AUTOSAR XML (schema 4.0)
standard types defined: float32, float64, sint16, sint32, sint8, uint16, uint32, uint8, void, boolean
package /ImplDataTypes
  7 x impl type, all with category=TYPE_REFERENCE, type-emitter=RTE:
    Impl_SensorPositionType: implementation-data-type=sint32
    Impl_SensorWeightType: implementation-data-type=uint32
    IoPositionSensorReadingType: implementation-data-type=Impl_SensorPositionType
    IoWeightSensorReadingType: implementation-data-type=Impl_SensorPositionType
    MultiStateBtnType: implementation-data-type=uint8
    SeatModeBtnType: implementation-data-type=boolean
    StepMotorStepType: implementation-data-type=uint8
package /MappingSets
  data type mapping set MappingSet: mode-request-type-map{implementation-data-type=uint8, mode-group=SeatCtrlMode}
package /PortInterfaces/ClientServer
  6 x client server interface:
    CsIf_IoGetSensorPosition
      operation Opr_IOGet
        arg position: type=IoPositionSensorReadingType, direction=OUT
    CsIf_IoGetSensorWeight
      operation Opr_IOGet
        arg weight: type=IoWeightSensorReadingType, direction=OUT
    CsIf_IoSetMotor
      operation Opr_IOSetForward
      operation Opr_IOSetReversed
    CsIf_PositionSensor
      operation Opr_GetPosition
        arg position: type=Impl_SensorPositionType, direction=OUT
    CsIf_StepMotor
      operation Opr_Move
        arg Arg_step: type=StepMotorStepType, direction=IN
    CsIf_WeightSensor
      operation GetWeight
        arg weight: type=Impl_SensorWeightType, direction=OUT
package /PortInterfaces/ModeSwitch
  mode switch interface MsIf_SeatCtrlMode
    mode group SeatCtrlMode: type=SeatCtrlMode
  mode declaration group SeatCtrlMode: category=ALPHABETIC_ORDER, initial-mode=INIT, on-transition-value=255
    mode AUTO
    mode INIT
    mode MANUAL
package /PortInterfaces/SenderReceiver
  sender receiver interface SrIf_SeatCtrlBtns
    data DE_HeightBtnState: type=MultiStateBtnType
    data DE_InclineBtnState: type=MultiStateBtnType
    data DE_SlideBtnState: type=MultiStateBtnType
  sender receiver interface SrIf_SeatCtrlData
    data DE_Height: type=uint8
    data DE_Incline: type=uint8
    data DE_Slide: type=uint8
  sender receiver interface SrIf_SeatModeBtn
    data SeatModeBtn: type=SeatModeBtnType
package /SoftwareComponents
  11 x swc implementation, all with programming-language=C, sw-version=1.0.0, vendor-id=255:
    Impl_SWC_ECU1: behavior=Ibhv_SWC_ECU1
      code-descriptors:
        code Code: artifact-descriptors=autosar-engineering-object={short-label=SWC.c, category=SWSRC}
      resource consumption ResourceConsumption
    Impl_SWC_HMI: behavior=Ibhv_SWC_HMI
      code-descriptors:
        code Code: artifact-descriptors=autosar-engineering-object={short-label=SWC.c, category=SWSRC}
      resource consumption ResourceConsumption
    Impl_SWC_HeightMotor: behavior=Ibhv_SWC_HeightMotor
      code-descriptors:
        code Code: artifact-descriptors=autosar-engineering-object={short-label=SWC.c, category=SWSRC}
      resource consumption ResourceConsumption
    Impl_SWC_HeightSensor: behavior=Ibhv_SWC_HeightSensor
      code-descriptors:
        code Code: artifact-descriptors=autosar-engineering-object={short-label=SWC.c, category=SWSRC}
      resource consumption ResourceConsumption
    Impl_SWC_InclineMotor: behavior=Ibhv_SWC_InclineMotor
      code-descriptors:
        code Code: artifact-descriptors=autosar-engineering-object={short-label=SWC.c, category=SWSRC}
      resource consumption ResourceConsumption
    Impl_SWC_InclineSensor: behavior=Ibhv_SWC_InclineSensor
      code-descriptors:
        code Code: artifact-descriptors=autosar-engineering-object={short-label=SWC.c, category=SWSRC}
      resource consumption ResourceConsumption
    Impl_SWC_IoHwAbs: behavior=Ibhv_SWC_IoHwAbs
      code-descriptors:
        code Code: artifact-descriptors=autosar-engineering-object={short-label=SWC.c, category=SWSRC}
      resource consumption ResourceConsumption
    Impl_SWC_SeatMgr: behavior=Ibhv_SWC_SeatMgr
      code-descriptors:
        code Code: artifact-descriptors=autosar-engineering-object={short-label=SWC.c, category=SWSRC}
      resource consumption ResourceConsumption
    Impl_SWC_SlideMotor: behavior=Ibhv_SWC_SlideMotor
      code-descriptors:
        code Code: artifact-descriptors=autosar-engineering-object={short-label=SWC.c, category=SWSRC}
      resource consumption ResourceConsumption
    Impl_SWC_SlideSensor: behavior=Ibhv_SWC_SlideSensor
      code-descriptors:
        code Code: artifact-descriptors=autosar-engineering-object={short-label=SWC.c, category=SWSRC}
      resource consumption ResourceConsumption
    Impl_SWC_WeightSensor: behavior=Ibhv_SWC_WeightSensor
      code-descriptors:
        code Code: artifact-descriptors=autosar-engineering-object={short-label=SWC.c, category=SWSRC}
      resource consumption ResourceConsumption
  application sw component type SWC_ECU1
    provide port pp_SeatCtrlData: provided-interface=SrIf_SeatCtrlData
    behavior Ibhv_SWC_ECU1: data-type-mapping=MappingSet, handle-termination-and-restart=NO-SUPPORT
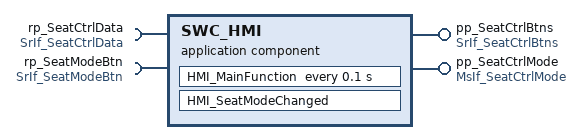
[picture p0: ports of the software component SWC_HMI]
  application sw component type SWC_HMI
    provide port pp_SeatCtrlBtns: provided-interface=SrIf_SeatCtrlBtns
    provide port pp_SeatCtrlMode: provided-interface=MsIf_SeatCtrlMode
    require port rp_SeatCtrlData: required-interface=SrIf_SeatCtrlData
    require port rp_SeatModeBtn: required-interface=SrIf_SeatModeBtn
    behavior Ibhv_SWC_HMI: data-type-mapping=MappingSet, handle-termination-and-restart=NO-SUPPORT
      data received event DRE_rp_SeatModeBtn_SeatModeBtn: start-on-event=HMI_SeatModeChanged, data=rp_SeatModeBtn.SeatModeBtn
      timing event TE_HMI_MainFunction_100ms: start-on-event=HMI_MainFunction, period=0.1
      runnable HMI_MainFunction
        data-receive-point-by-arguments:
          access DRP_rp_SeatCtrlData_DE_Height: accessed-variable=rp_SeatCtrlData.DE_Height
          access DRP_rp_SeatCtrlData_DE_Incline: accessed-variable=rp_SeatCtrlData.DE_Incline
          access DRP_rp_SeatCtrlData_DE_Slide: accessed-variable=rp_SeatCtrlData.DE_Slide
        data-send-points:
          access DSP_pp_SeatCtrlBtns_DE_HeightBtnState: accessed-variable=pp_SeatCtrlBtns.DE_HeightBtnState
          access DSP_pp_SeatCtrlBtns_DE_InclineBtnState: accessed-variable=pp_SeatCtrlBtns.DE_InclineBtnState
          access DSP_pp_SeatCtrlBtns_DE_SlideBtnState: accessed-variable=pp_SeatCtrlBtns.DE_SlideBtnState
      runnable HMI_SeatModeChanged
        data-receive-point-by-arguments:
          access DRP_rp_SeatModeBtn_SeatModeBtn: accessed-variable=rp_SeatModeBtn.SeatModeBtn
        mode switch point MSP_pp_SeatCtrlMode_pp_SeatCtrlMode: mode-group=pp_SeatCtrlMode.SeatCtrlMode
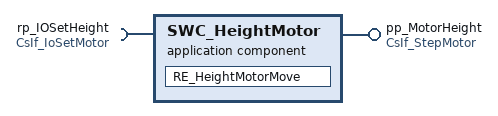
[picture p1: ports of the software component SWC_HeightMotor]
  application sw component type SWC_HeightMotor
    provide port pp_MotorHeight: provided-interface=CsIf_StepMotor
    require port rp_IOSetHeight: required-interface=CsIf_IoSetMotor
    behavior Ibhv_SWC_HeightMotor: data-type-mapping=MappingSet, handle-termination-and-restart=NO-SUPPORT
      operation invoked event OIE_pp_MotorHeight_Opr_Move: start-on-event=RE_HeightMotorMove, operation=pp_MotorHeight.Opr_Move
      runnable RE_HeightMotorMove
        sync call SCP_rp_IOSetHeight_Opr_IOSetForward: operation=rp_IOSetHeight.Opr_IOSetForward, timeout=0.0
        sync call SCP_rp_IOSetHeight_Opr_IOSetReversed: operation=rp_IOSetHeight.Opr_IOSetReversed, timeout=0.0
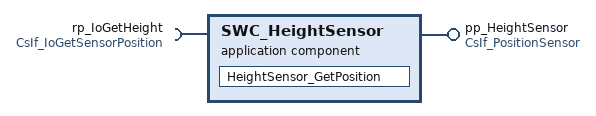
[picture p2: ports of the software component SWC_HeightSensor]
  application sw component type SWC_HeightSensor
    provide port pp_HeightSensor: provided-interface=CsIf_PositionSensor
    require port rp_IoGetHeight: required-interface=CsIf_IoGetSensorPosition
    behavior Ibhv_SWC_HeightSensor: data-type-mapping=MappingSet, handle-termination-and-restart=NO-SUPPORT
      operation invoked event OIE_pp_HeightSensor_Opr_GetPosition: start-on-event=HeightSensor_GetPosition, operation=pp_HeightSensor.Opr_GetPosition
      runnable HeightSensor_GetPosition
        sync call SCP_rp_IoGetHeight_Opr_IOGet: operation=rp_IoGetHeight.Opr_IOGet, timeout=0.0
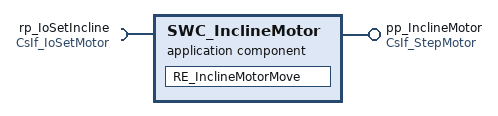
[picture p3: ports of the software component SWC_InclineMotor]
  application sw component type SWC_InclineMotor
    provide port pp_InclineMotor: provided-interface=CsIf_StepMotor
    require port rp_IoSetIncline: required-interface=CsIf_IoSetMotor
    behavior Ibhv_SWC_InclineMotor: data-type-mapping=MappingSet, handle-termination-and-restart=NO-SUPPORT
      operation invoked event OIE_pp_InclineMotor_Opr_Move: start-on-event=RE_InclineMotorMove, operation=pp_InclineMotor.Opr_Move
      runnable RE_InclineMotorMove
        sync call SCP_rp_IoSetIncline_Opr_IOSetForward: operation=rp_IoSetIncline.Opr_IOSetForward, timeout=0.0
        sync call SCP_rp_IoSetIncline_Opr_IOSetReversed: operation=rp_IoSetIncline.Opr_IOSetReversed, timeout=0.0
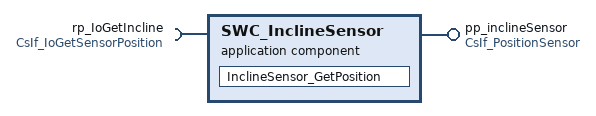
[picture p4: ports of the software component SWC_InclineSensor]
  application sw component type SWC_InclineSensor
    provide port pp_inclineSensor: provided-interface=CsIf_PositionSensor
    require port rp_IoGetIncline: required-interface=CsIf_IoGetSensorPosition
    behavior Ibhv_SWC_InclineSensor: data-type-mapping=MappingSet, handle-termination-and-restart=NO-SUPPORT
      operation invoked event OIE_pp_inclineSensor_Opr_GetPosition: start-on-event=InclineSensor_GetPosition, operation=pp_inclineSensor.Opr_GetPosition
      runnable InclineSensor_GetPosition
        sync call SCP_rp_IoGetIncline_Opr_IOGet: operation=rp_IoGetIncline.Opr_IOGet, timeout=0.0
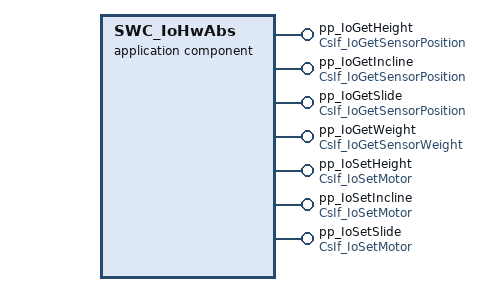
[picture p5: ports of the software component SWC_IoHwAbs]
  application sw component type SWC_IoHwAbs
    7 x provide port:
      pp_IoGetHeight: provided-interface=CsIf_IoGetSensorPosition
      pp_IoGetIncline: provided-interface=CsIf_IoGetSensorPosition
      pp_IoGetSlide: provided-interface=CsIf_IoGetSensorPosition
      pp_IoGetWeight: provided-interface=CsIf_IoGetSensorWeight
      pp_IoSetHeight: provided-interface=CsIf_IoSetMotor
      pp_IoSetIncline: provided-interface=CsIf_IoSetMotor
      pp_IoSetSlide: provided-interface=CsIf_IoSetMotor
    behavior Ibhv_SWC_IoHwAbs: data-type-mapping=MappingSet, handle-termination-and-restart=NO-SUPPORT
      10 x operation invoked event:
        OIE_pp_IoGetHeight_Opr_IOGet: start-on-event=IOHwAbs_ECU_GetHeight, operation=pp_IoGetHeight.Opr_IOGet
        OIE_pp_IoGetIncline_Opr_IOGet: start-on-event=IOHwAbs_ECU_GetIncline, operation=pp_IoGetIncline.Opr_IOGet
        OIE_pp_IoGetSlide_Opr_IOGet: start-on-event=IOHwAbs_ECU_GetSlide, operation=pp_IoGetSlide.Opr_IOGet
        OIE_pp_IoGetWeight_Opr_IOGet: start-on-event=IOHwAbs_ECU_GetWeight, operation=pp_IoGetWeight.Opr_IOGet
        OIE_pp_IoSetHeight_Opr_IOSetForward: start-on-event=IOHwAbs_ECU_SetForwardHeight, operation=pp_IoSetHeight.Opr_IOSetForward
        OIE_pp_IoSetHeight_Opr_IOSetReversed: start-on-event=IOHwAbs_ECU_SetReverseHeight, operation=pp_IoSetHeight.Opr_IOSetReversed
        OIE_pp_IoSetIncline_Opr_IOSetForward: start-on-event=IOHwAbs_ECU_SetForwardIncline, operation=pp_IoSetIncline.Opr_IOSetForward
        OIE_pp_IoSetIncline_Opr_IOSetReversed: start-on-event=IOHwAbs_ECU_SetReverseIncline, operation=pp_IoSetIncline.Opr_IOSetReversed
        OIE_pp_IoSetSlide_Opr_IOSetForward: start-on-event=IOHwAbs_ECU_SetForwardSlide, operation=pp_IoSetSlide.Opr_IOSetForward
        OIE_pp_IoSetSlide_Opr_IOSetReversed: start-on-event=IOHwAbs_ECU_SetReverseSlide, operation=pp_IoSetSlide.Opr_IOSetReversed
      10 x runnable:
        IOHwAbs_ECU_GetHeight
        IOHwAbs_ECU_GetIncline
        IOHwAbs_ECU_GetSlide
        IOHwAbs_ECU_GetWeight
        IOHwAbs_ECU_SetForwardHeight
        IOHwAbs_ECU_SetForwardIncline
        IOHwAbs_ECU_SetForwardSlide
        IOHwAbs_ECU_SetReverseHeight
        IOHwAbs_ECU_SetReverseIncline
        IOHwAbs_ECU_SetReverseSlide
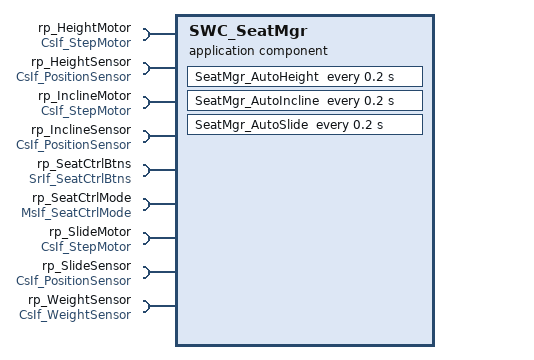
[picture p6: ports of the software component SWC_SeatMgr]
  application sw component type SWC_SeatMgr
    9 x require port:
      rp_HeightMotor: required-interface=CsIf_StepMotor
      rp_HeightSensor: required-interface=CsIf_PositionSensor
      rp_InclineMotor: required-interface=CsIf_StepMotor
      rp_InclineSensor: required-interface=CsIf_PositionSensor
      rp_SeatCtrlBtns: required-interface=SrIf_SeatCtrlBtns
      rp_SeatCtrlMode: required-interface=MsIf_SeatCtrlMode
      rp_SlideMotor: required-interface=CsIf_StepMotor
      rp_SlideSensor: required-interface=CsIf_PositionSensor
      rp_WeightSensor: required-interface=CsIf_WeightSensor
    behavior Ibhv_SWC_SeatMgr: data-type-mapping=MappingSet, handle-termination-and-restart=NO-SUPPORT
      data received event DRE_rp_SeatCtrlBtns_DE_HeightBtnState: start-on-event=SeatMgr_SetHeight, data=rp_SeatCtrlBtns.DE_HeightBtnState
      data received event DRE_rp_SeatCtrlBtns_DE_InclineBtnState: start-on-event=SeatMgr_SetIncline, data=rp_SeatCtrlBtns.DE_InclineBtnState
      data received event DRE_rp_SeatCtrlBtns_DE_SlideBtnState: start-on-event=SeatMgr_SetSlide, data=rp_SeatCtrlBtns.DE_SlideBtnState
      timing event TE_SeatMgr_AutoHeight_200ms: start-on-event=SeatMgr_AutoHeight, period=0.2
      timing event TE_SeatMgr_AutoIncline_200ms: start-on-event=SeatMgr_AutoIncline, period=0.2
      timing event TE_SeatMgr_AutoSlide_200ms: start-on-event=SeatMgr_AutoSlide, period=0.2
      6 x runnable:
        SeatMgr_AutoHeight
          sync call SCP_rp_HeightMotor_Opr_Move: operation=rp_HeightMotor.Opr_Move, timeout=0.0
          sync call SCP_rp_HeightSensor_Opr_GetPosition: operation=rp_HeightSensor.Opr_GetPosition, timeout=0.0
          sync call SCP_rp_WeightSensor_GetWeight: operation=rp_WeightSensor.GetWeight, timeout=0.0
        SeatMgr_AutoIncline
          sync call SCP_rp_InclineMotor_Opr_Move: operation=rp_InclineMotor.Opr_Move, timeout=0.0
          sync call SCP_rp_InclineSensor_Opr_GetPosition: operation=rp_InclineSensor.Opr_GetPosition, timeout=0.0
          sync call SCP_rp_WeightSensor_GetWeight: operation=rp_WeightSensor.GetWeight, timeout=0.0
        SeatMgr_AutoSlide
          sync call SCP_rp_SlideMotor_Opr_Move: operation=rp_SlideMotor.Opr_Move, timeout=0.0
          sync call SCP_rp_SlideSensor_Opr_GetPosition: operation=rp_SlideSensor.Opr_GetPosition, timeout=0.0
          sync call SCP_rp_WeightSensor_GetWeight: operation=rp_WeightSensor.GetWeight, timeout=0.0
        SeatMgr_SetHeight
          data-receive-point-by-arguments:
            access DRP_rp_SeatCtrlBtns_DE_HeightBtnState: accessed-variable=rp_SeatCtrlBtns.DE_HeightBtnState
          sync call SCP_rp_HeightMotor_Opr_Move: operation=rp_HeightMotor.Opr_Move, timeout=0.0
        SeatMgr_SetIncline
          data-receive-point-by-arguments:
            access DRP_rp_SeatCtrlBtns_DE_InclineBtnState: accessed-variable=rp_SeatCtrlBtns.DE_InclineBtnState
          sync call SCP_rp_InclineMotor_Opr_Move: operation=rp_InclineMotor.Opr_Move, timeout=0.0
        SeatMgr_SetSlide
          data-receive-point-by-arguments:
            access DRP_rp_SeatCtrlBtns_DE_SlideBtnState: accessed-variable=rp_SeatCtrlBtns.DE_SlideBtnState
          sync call SCP_rp_SlideMotor_Opr_Move: operation=rp_SlideMotor.Opr_Move, timeout=0.0
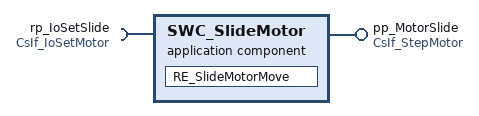
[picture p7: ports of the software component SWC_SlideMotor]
  application sw component type SWC_SlideMotor
    provide port pp_MotorSlide: provided-interface=CsIf_StepMotor
    require port rp_IoSetSlide: required-interface=CsIf_IoSetMotor
    behavior Ibhv_SWC_SlideMotor: data-type-mapping=MappingSet, handle-termination-and-restart=NO-SUPPORT
      operation invoked event OIE_pp_MotorSlide_Opr_Move: start-on-event=RE_SlideMotorMove, operation=pp_MotorSlide.Opr_Move
      runnable RE_SlideMotorMove
        sync call SCP_rp_IoSetSlide_Opr_IOSetForward: operation=rp_IoSetSlide.Opr_IOSetForward, timeout=0.0
        sync call SCP_rp_IoSetSlide_Opr_IOSetReversed: operation=rp_IoSetSlide.Opr_IOSetReversed, timeout=0.0
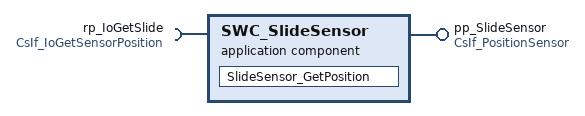
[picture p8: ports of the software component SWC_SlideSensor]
  application sw component type SWC_SlideSensor
    provide port pp_SlideSensor: provided-interface=CsIf_PositionSensor
    require port rp_IoGetSlide: required-interface=CsIf_IoGetSensorPosition
    behavior Ibhv_SWC_SlideSensor: data-type-mapping=MappingSet, handle-termination-and-restart=NO-SUPPORT
      operation invoked event OIE_pp_SlideSensor_Opr_GetPosition: start-on-event=SlideSensor_GetPosition, operation=pp_SlideSensor.Opr_GetPosition
      runnable SlideSensor_GetPosition
        sync call SCP_rp_IoGetSlide_Opr_IOGet: operation=rp_IoGetSlide.Opr_IOGet, timeout=0.0
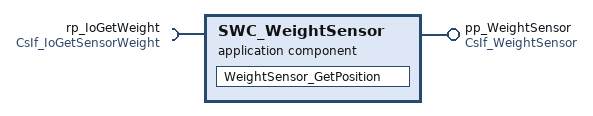
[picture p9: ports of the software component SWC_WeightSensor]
  application sw component type SWC_WeightSensor
    provide port pp_WeightSensor: provided-interface=CsIf_WeightSensor
    require port rp_IoGetWeight: required-interface=CsIf_IoGetSensorWeight
    behavior Ibhv_SWC_WeightSensor: data-type-mapping=MappingSet, handle-termination-and-restart=NO-SUPPORT
      operation invoked event OIE_pp_WeightSensor_GetWeight: start-on-event=WeightSensor_GetPosition, operation=pp_WeightSensor.GetWeight
      runnable WeightSensor_GetPosition
        sync call SCP_rp_IoGetWeight_Opr_IOGet: operation=rp_IoGetWeight.Opr_IOGet, timeout=0.0
package /Compositions
  composition sw component type SeatCtrlComposition
    10 x component:
      SWC_HMI: type=SWC_HMI
      SWC_HeightMotor: type=SWC_HeightMotor
      SWC_HeightSensor: type=SWC_HeightSensor
      SWC_InclineMotor: type=SWC_InclineMotor
      SWC_InclineSensor: type=SWC_InclineSensor
      SWC_IoHwAbs: type=SWC_IoHwAbs
      SWC_SeatMgr: type=SWC_SeatMgr
      SWC_SlideMotor: type=SWC_SlideMotor
      SWC_SlideSensor: type=SWC_SlideSensor
      SWC_WeightSensor: type=SWC_WeightSensor
    connect SWC_HMI.pp_SeatCtrlMode -> SWC_SeatMgr.rp_SeatCtrlMode
    connect SWC_HeightMotor.pp_MotorHeight -> SWC_SeatMgr.rp_HeightMotor
    connect SWC_HeightSensor.pp_HeightSensor -> SWC_SeatMgr.rp_HeightSensor
    connect SWC_InclineMotor.pp_InclineMotor -> SWC_SeatMgr.rp_InclineMotor
    connect SWC_InclineSensor.pp_inclineSensor -> SWC_SeatMgr.rp_InclineSensor
    connect SWC_IoHwAbs.pp_IoGetHeight -> SWC_HeightSensor.rp_IoGetHeight
    connect SWC_IoHwAbs.pp_IoGetIncline -> SWC_InclineSensor.rp_IoGetIncline
    connect SWC_IoHwAbs.pp_IoGetSlide -> SWC_SlideSensor.rp_IoGetSlide
    connect SWC_IoHwAbs.pp_IoGetWeight -> SWC_WeightSensor.rp_IoGetWeight
    connect SWC_IoHwAbs.pp_IoSetHeight -> SWC_HeightMotor.rp_IOSetHeight
    connect SWC_IoHwAbs.pp_IoSetIncline -> SWC_InclineMotor.rp_IoSetIncline
    connect SWC_IoHwAbs.pp_IoSetSlide -> SWC_SlideMotor.rp_IoSetSlide
    connect SWC_SlideMotor.pp_MotorSlide -> SWC_SeatMgr.rp_SlideMotor
    connect SWC_SlideSensor.pp_SlideSensor -> SWC_SeatMgr.rp_SlideSensor
    connect SWC_WeightSensor.pp_WeightSensor -> SWC_SeatMgr.rp_WeightSensor
